# LPC176x5x register map
File version: 0.2
CPU: CM3 r0p0, little endian, no MPU, no FPU, 0x5 interrupt priority bits, 0x0 interrupts
Registers are 32-bit, read-write, no defined reset value unless marked. A register's access mark holds for its fields unless they carry their own. Offsets are from the block's base; [hi:lo] are bit positions; {n}, {i} and the like mark numbered series; 'fields as' and 'values as' point back to an identical list.

## CAN1 — CAN1 controller
Base 0x40044000
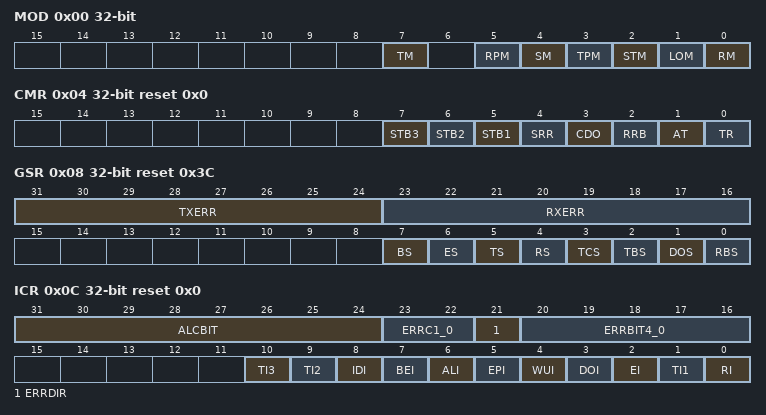
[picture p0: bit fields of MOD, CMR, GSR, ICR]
0x00 MOD — Controls the operating mode of the CAN Controller.
  [7] TM — Test Mode.
    0=DISABLED_NORMAL_OPE (Disabled. Normal operation.); 1=ENABLED_THE_TD_PIN_ (Enabled. The TD pin will reflect the bit, detected on RD pin, with the next positive edge of the system clock.)
  [5] RPM — Receive Polarity Mode.
    0=LOW_ACTIVE_RD_INPUT (Low active. RD input is active Low (dominant bit = 0).); 1=HIGH_ACTIVE_RD_INPU (High active. RD input is active High (dominant bit = 1) -- reverse polarity.)
  [4] SM — Sleep Mode.
    0=WAKE_UP_NORMAL_OPER (Wake-up. Normal operation.); 1=SLEEP_THE_CAN_CONTR (Sleep. The CAN controller enters Sleep Mode if no CAN interrupt is pending and there is no bus activity. See the Sleep Mode description Section 21.8.2 on page 565.)
  [3] TPM — Transmit Priority Mode.
    0=CAN_ID_THE_TRANSMIT (CAN ID. The transmit priority for 3 Transmit Buffers depends on the CAN Identifier.); 1=LOCAL_PRIORITY_THE_ (Local priority. The transmit priority for 3 Transmit Buffers depends on the contents of the Tx Priority register within the Transmit Buffer.)
  [2] STM — Self Test Mode.
    0=NORMAL_A_TRANSMITTE (Normal. A transmitted message must be acknowledged to be considered successful.); 1=SELF_TEST_THE_CONTR (Self test. The controller will consider a Tx message successful even if there is no acknowledgment received. In this mode a full node test is possible without any other active node on the bus using the SRR bit in CANxCMR.)
  [1] LOM — Listen Only Mode.
    0=NORMAL_THE_CAN_CONT (Normal. The CAN controller acknowledges a successfully received message on the CAN bus. The error counters are stopped at the current value.); 1=LISTEN_ONLY_THE_CON (Listen only. The controller gives no acknowledgment, even if a message is successfully received. Messages cannot be sent, and the controller operates in error passive mode. This mode is intended for software bit rate detection and hot plugging.)
  [0] RM — Reset Mode.
    0=NORMAL_THE_CAN_CONTR (Normal.The CAN Controller is in the Operating Mode, and certain registers can not be written.); 1=RESET_CAN_OPERATION (Reset. CAN operation is disabled, writable registers can be written and the current transmission/reception of a message is aborted.)
0x04 CMR wo reset 0x0 — Command bits that affect the state of the CAN Controller
  [7] STB3 — Select Tx Buffer 3.
    0=NOT_SELECTED_TX_BUF (Not selected. Tx Buffer 3 is not selected for transmission.); 1=SELECTED_TX_BUFFER_ (Selected. Tx Buffer 3 is selected for transmission.)
  [6] STB2 — Select Tx Buffer 2.
    0=NOT_SELECTED_TX_BUF (Not selected. Tx Buffer 2 is not selected for transmission.); 1=SELECTED_TX_BUFFER_ (Selected. Tx Buffer 2 is selected for transmission.)
  [5] STB1 — Select Tx Buffer 1.
    0=NOT_SELECTED_TX_BUF (Not selected. Tx Buffer 1 is not selected for transmission.); 1=SELECTED_TX_BUFFER_ (Selected. Tx Buffer 1 is selected for transmission.)
  [4] SRR — Self Reception Request.
    0=ABSENT_NO_SELF_RECE (Absent. No self reception request.); 1=PRESENT_THE_MESSAGE (Present. The message, previously written to the CANxTFS, CANxTID, and optionally the CANxTDA and CANxTDB registers, is queued for transmission from the selected Transmit Buffer and received simultaneously. This differs from the TR bit above in that the receiver is not disabled during the transmission, so that it receives the message if its Identifier is recognized by the Acceptance Filter.)
  [3] CDO — Clear Data Overrun.
    0=NO_ACTION_DO_NOT_CL (No action. Do not clear the data overrun bit.); 1=CLEAR_THE_DATA_OVER (Clear. The Data Overrun bit in Status Register(s) is cleared.)
  [2] RRB — Release Receive Buffer.
    0=NO_ACTION_DO_NOT_RE (No action. Do not release the receive buffer.); 1=RELEASED_THE_INFORM (Released. The information in the Receive Buffer (consisting of CANxRFS, CANxRID, and if applicable the CANxRDA and CANxRDB registers) is released, and becomes eligible for replacement by the next received frame. If the next received frame is not available, writing this command clears the RBS bit in the Status Register(s).)
  [1] AT — Abort Transmission.
    0=NO_ACTION_DO_NOT_AB (No action. Do not abort the transmission.); 1=PRESENT_IF_NOT_ALRE (Present. if not already in progress, a pending Transmission Request for the selected Transmit Buffer is cancelled.)
  [0] TR — Transmission Request.
    0=ABSENT_NO_TRANSMISSI (Absent.No transmission request.); 1=PRESENT_THE_MESSAGE (Present. The message, previously written to the CANxTFI, CANxTID, and optionally the CANxTDA and CANxTDB registers, is queued for transmission from the selected Transmit Buffer. If at two or all three of STB1, STB2 and STB3 bits are selected when TR=1 is written, Transmit Buffer will be selected based on the chosen priority scheme (for details see Section 21.5.3 Transmit Buffers (TXB)))
0x08 GSR ro reset 0x3C — Global Controller Status and Error Counters. The error counters can only be written when RM in CANMOD is 1.
  [31:24] TXERR — The current value of the Tx Error Counter (an 8-bit value).
  [23:16] RXERR — The current value of the Rx Error Counter (an 8-bit value).
  [7] BS — Bus Status. Mode bit '1' (present) and an Error Warning Interrupt is generated, if enabled. Afterwards the Transmit Error Counter is set to '127', and the Receive Error Counter is cleared. It will stay in this mode until the CPU clears the Reset Mode bit. Once this is completed the CAN Controller will wait the minimum protocol-defined time (128 occurrences of the Bus-Free signal) counting down the Transmit Error Counter. After that, the Bus Status bit is cleared (Bus-On), the Error Status bit is set '0' (ok), the Error Counters are reset, and an Error Warning Interrupt is generated, if enabled. Reading the TX Error Counter during this time gives information about the status of the Bus-Off recovery.
    0=BUS_ON_THE_CAN_CONT (Bus-on. The CAN Controller is involved in bus activities); 1=BUS_OFF_THE_CAN_CON (Bus-off. The CAN controller is currently not involved/prohibited from bus activity because the Transmit Error Counter reached its limiting value of 255.)
  [6] ES — Error Status. Errors detected during reception or transmission will effect the error counters according to the CAN specification. The Error Status bit is set when at least one of the error counters has reached or exceeded the Error Warning Limit. An Error Warning Interrupt is generated, if enabled. The default value of the Error Warning Limit after hardware reset is 96 decimal, see also Section 21.7.7 CAN Error Warning Limit register (CAN1EWL - 0x4004 4018, CAN2EWL - 0x4004 8018).
    0=OK_BOTH_ERROR_COUNT (OK. Both error counters are below the Error Warning Limit.); 1=ERROR_ONE_OR_BOTH_O (Error. One or both of the Transmit and Receive Error Counters has reached the limit set in the Error Warning Limit register.)
  [5] TS — Transmit Status. If both the Receive Status and the Transmit Status bits are '0' (idle), the CAN-Bus is idle. If both bits are set, the controller is waiting to become idle again. After hardware reset 11 consecutive recessive bits have to be detected until idle status is reached. After Bus-off this will take 128 times of 11 consecutive recessive bits.
    0=IDLE_THE_CAN_CONTRO (Idle. The CAN controller is idle.); 1=TRANSMIT_THE_CAN_CO (Transmit. The CAN controller is sending a message.)
  [4] RS — Receive Status. If both the Receive Status and the Transmit Status bits are '0' (idle), the CAN-Bus is idle. If both bits are set, the controller is waiting to become idle again. After hardware reset 11 consecutive recessive bits have to be detected until idle status is reached. After Bus-off this will take 128 times of 11 consecutive recessive bits.
    0=IDLE_THE_CAN_CONTRO (Idle. The CAN controller is idle.); 1=RECEIVE_THE_CAN_CON (Receive. The CAN controller is receiving a message.)
  [3] TCS — Transmit Complete Status. The Transmission Complete Status bit is set '0' (incomplete) whenever the Transmission Request bit or the Self Reception Request bit is set '1' at least for one of the three Transmit Buffers. The Transmission Complete Status bit will remain '0' until all messages are transmitted successfully.
    0=INCOMPLETE_AT_LEAST (Incomplete. At least one requested transmission has not been successfully completed yet.); 1=COMPLETE_ALL_REQUES (Complete. All requested transmission(s) has (have) been successfully completed.)
  [2] TBS — Transmit Buffer Status.
    0=LOCKED_AT_LEAST_ONE (Locked. At least one of the Transmit Buffers is not available for the CPU, i.e. at least one previously queued message for this CAN controller has not yet been sent, and therefore software should not write to the CANxTFI, CANxTID, CANxTDA, nor CANxTDB registers of that (those) Tx buffer(s).); 1=RELEASED_ALL_THREE_ (Released. All three Transmit Buffers are available for the CPU. No transmit message is pending for this CAN controller (in any of the 3 Tx buffers), and software may write to any of the CANxTFI, CANxTID, CANxTDA, and CANxTDB registers.)
  [1] DOS — Data Overrun Status. If there is not enough space to store the message within the Receive Buffer, that message is dropped and the Data Overrun condition is signalled to the CPU in the moment this message becomes valid. If this message is not completed successfully (e.g. because of an error), no overrun condition is signalled.
    0=ABSENT_NO_DATA_OVER (Absent. No data overrun has occurred since the last Clear Data Overrun command was given/written to CANxCMR (or since Reset).); 1=OVERRUN_A_MESSAGE_W (Overrun. A message was lost because the preceding message to this CAN controller was not read and released quickly enough (there was not enough space for a new message in the Double Receive Buffer).)
  [0] RBS — Receive Buffer Status. After reading all messages and releasing their memory space with the command 'Release Receive Buffer,' this bit is cleared.
    0=EMPTY_NO_MESSAGE_IS (Empty. No message is available.); 1=FULL_AT_LEAST_ONE_C (Full. At least one complete message is received by the Double Receive Buffer and available in the CANxRFS, CANxRID, and if applicable the CANxRDA and CANxRDB registers. This bit is cleared by the Release Receive Buffer command in CANxCMR, if no subsequent received message is available.)
0x0C ICR ro reset 0x0 — Interrupt status, Arbitration Lost Capture, Error Code Capture
  [31:24] ALCBIT — Each time arbitration is lost while trying to send on the CAN, the bit number within the frame is captured into this field. After the content of ALCBIT is read, the ALI bit is cleared and a new Arbitration Lost interrupt can occur. 00 = arbitration lost in the first bit (MS) of identifier ... 11 = arbitration lost in SRTS bit (RTR bit for standard frame messages) 12 = arbitration lost in IDE bit 13 = arbitration lost in 12th bit of identifier (extended frame only) ... 30 = arbitration lost in last bit of identifier (extended frame only) 31 = arbitration lost in RTR bit (extended frame only) On arbitration lost, the corresponding arbitration lost interrupt is forced, if enabled. At that time, the current bit position of the Bit Stream Processor is captured into the Arbitration Lost Capture Register. The content within this register is fixed until the user application has read out its contents once. From now on, the capture mechanism is activated again.
  [23:22] ERRC1_0 — When the CAN controller detects a bus error, the type of error is captured in this field:
    0=BIT_ERROR; 1=FORM_ERROR; 2=STUFF_ERROR; 3=OTHER_ERROR
  [21] ERRDIR — When the CAN controller detects a bus error, the direction of the current bit is captured in this bit.
    0=ERROR_OCCURRED_DURIN (Error occurred during transmitting.); 1=ERROR_OCCURRED_DURIN (Error occurred during receiving.)
  [20:16] ERRBIT4_0 — Error Code Capture: when the CAN controller detects a bus error, the location of the error within the frame is captured in this field. The value reflects an internal state variable, and as a result is not very linear: 00011 = Start of Frame 00010 = ID28 ... ID21 00110 = ID20 ... ID18 00100 = SRTR Bit 00101 = IDE bit 00111 = ID17 ... 13 01111 = ID12 ... ID5 01110 = ID4 ... ID0 01100 = RTR Bit 01101 = Reserved Bit 1 01001 = Reserved Bit 0 01011 = Data Length Code 01010 = Data Field 01000 = CRC Sequence 11000 = CRC Delimiter 11001 = Acknowledge Slot 11011 = Acknowledge Delimiter 11010 = End of Frame 10010 = Intermission Whenever a bus error occurs, the corresponding bus error interrupt is forced, if enabled. At the same time, the current position of the Bit Stream Processor is captured into the Error Code Capture Register. The content within this register is fixed until the user software has read out its content once. From now on, the capture mechanism is activated again, i.e. reading the CANxICR enables another Bus Error Interrupt.
  [10] TI3 — Transmit Interrupt 3. This bit is set when the TBS3 bit in CANxSR goes from 0 to 1 (whenever a message out of TXB3 was successfully transmitted or aborted), indicating that Transmit buffer 3 is available, and the TIE3 bit in CANxIER is 1.
    0=RESET; 1=SET
  [9] TI2 — Transmit Interrupt 2. This bit is set when the TBS2 bit in CANxSR goes from 0 to 1 (whenever a message out of TXB2 was successfully transmitted or aborted), indicating that Transmit buffer 2 is available, and the TIE2 bit in CANxIER is 1.
    0=RESET; 1=SET
  [8] IDI — ID Ready Interrupt -- this bit is set if the IDIE bit in CANxIER is 1, and a CAN Identifier has been received (a message was successfully transmitted or aborted). This bit is set whenever a message was successfully transmitted or aborted and the IDIE bit is set in the IER register.
    0=RESET; 1=SET
  [7] BEI — Bus Error Interrupt -- this bit is set if the BEIE bit in CANxIER is 1, and the CAN controller detects an error on the bus.
    0=RESET; 1=SET
  [6] ALI — Arbitration Lost Interrupt. This bit is set if the ALIE bit in CANxIER is 1, and the CAN controller loses arbitration while attempting to transmit. In this case the CAN node becomes a receiver.
    0=RESET; 1=SET
  [5] EPI — Error Passive Interrupt. This bit is set if the EPIE bit in CANxIER is 1, and the CAN controller switches between Error Passive and Error Active mode in either direction. This is the case when the CAN Controller has reached the Error Passive Status (at least one error counter exceeds the CAN protocol defined level of 127) or if the CAN Controller is in Error Passive Status and enters the Error Active Status again.
    0=RESET; 1=SET
  [4] WUI — Wake-Up Interrupt. This bit is set if the CAN controller is sleeping and bus activity is detected and the WUIE bit in CANxIER is 1. A Wake-Up Interrupt is also generated if the CPU tries to set the Sleep bit while the CAN controller is involved in bus activities or a CAN Interrupt is pending. The WUI flag can also get asserted when the according enable bit WUIE is not set. In this case a Wake-Up Interrupt does not get asserted.
    0=RESET; 1=SET
  [3] DOI — Data Overrun Interrupt. This bit is set when the DOS bit in CANxSR goes from 0 to 1 and the DOIE bit in CANxIER is 1.
    0=RESET; 1=SET
  [2] EI — Error Warning Interrupt. This bit is set on every change (set or clear) of either the Error Status or Bus Status bit in CANxSR and the EIE bit bit is set within the Interrupt Enable Register at the time of the change.
    0=RESET; 1=SET
  [1] TI1 — Transmit Interrupt 1. This bit is set when the TBS1 bit in CANxSR goes from 0 to 1 (whenever a message out of TXB1 was successfully transmitted or aborted), indicating that Transmit buffer 1 is available, and the TIE1 bit in CANxIER is 1.
    0=RESET; 1=SET
  [0] RI — Receive Interrupt. This bit is set whenever the RBS bit in CANxSR and the RIE bit in CANxIER are both 1, indicating that a new message was received and stored in the Receive Buffer. The Receive Interrupt Bit is not cleared upon a read access to the Interrupt Register. Giving the Command Release Receive Buffer will clear RI temporarily. If there is another message available within the Receive Buffer after the release command, RI is set again. Otherwise RI remains cleared.
    0=RESET; 1=SET
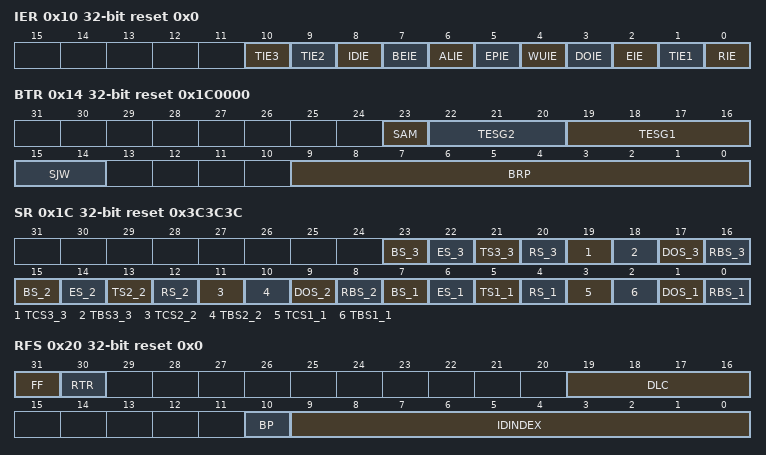
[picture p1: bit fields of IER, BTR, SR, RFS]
0x10 IER reset 0x0 — Interrupt Enable
  [10] TIE3 — Transmit Interrupt Enable for Buffer3. When a message has been successfully transmitted out of TXB3 or Transmit Buffer 3 is accessible again (e.g. after an Abort Transmission command), the CAN Controller requests the respective interrupt.
  [9] TIE2 — Transmit Interrupt Enable for Buffer2. When a message has been successfully transmitted out of TXB2 or Transmit Buffer 2 is accessible again (e.g. after an Abort Transmission command), the CAN Controller requests the respective interrupt.
  [8] IDIE — ID Ready Interrupt Enable. When a CAN identifier has been received, the CAN Controller requests the respective interrupt.
  [7] BEIE — Bus Error Interrupt Enable. If a bus error has been detected, the CAN Controller requests the respective interrupt.
  [6] ALIE — Arbitration Lost Interrupt Enable. If the CAN Controller has lost arbitration, the respective interrupt is requested.
  [5] EPIE — Error Passive Interrupt Enable. If the error status of the CAN Controller changes from error active to error passive or vice versa, the respective interrupt is requested.
  [4] WUIE — Wake-Up Interrupt Enable. If the sleeping CAN controller wakes up, the respective interrupt is requested.
  [3] DOIE — Data Overrun Interrupt Enable. If the Data Overrun Status bit is set (see Status Register), the CAN Controller requests the respective interrupt.
  [2] EIE — Error Warning Interrupt Enable. If the Error or Bus Status change (see Status Register), the CAN Controller requests the respective interrupt.
  [1] TIE1 — Transmit Interrupt Enable for Buffer1. When a message has been successfully transmitted out of TXB1 or Transmit Buffer 1 is accessible again (e.g. after an Abort Transmission command), the CAN Controller requests the respective interrupt.
  [0] RIE — Receiver Interrupt Enable. When the Receive Buffer Status is 'full', the CAN Controller requests the respective interrupt.
0x14 BTR reset 0x1C0000 — Bus Timing. Can only be written when RM in CANMOD is 1.
  [23] SAM — Sampling
    0=THE_BUS_IS_SAMPLED_O (The bus is sampled once (recommended for high speed buses)); 1=THE_BUS_IS_SAMPLED_3 (The bus is sampled 3 times (recommended for low to medium speed buses to filter spikes on the bus-line))
  [22:20] TESG2 — The delay from the sample point to the next nominal sync point is (this value plus one) CAN clocks. The nominal CAN bit time is (this value plus the value in TSEG1 plus 3) CAN clocks.
  [19:16] TESG1 — The delay from the nominal Sync point to the sample point is (this value plus one) CAN clocks.
  [15:14] SJW — The Synchronization Jump Width is (this value plus one) CAN clocks.
  [9:0] BRP — Baud Rate Prescaler. The APB clock is divided by (this value plus one) to produce the CAN clock.
0x18 EWL reset 0x60 — Error Warning Limit. Can only be written when RM in CANMOD is 1.
  [7:0] EWL — During CAN operation, this value is compared to both the Tx and Rx Error Counters. If either of these counter matches this value, the Error Status (ES) bit in CANSR is set.
0x1C SR ro reset 0x3C3C3C — Status Register
  [23] BS_3 — Bus Status. This bit is identical to the BS bit in the CANxGSR.
  [22] ES_3 — Error Status. This bit is identical to the ES bit in the CANxGSR.
  [21] TS3_3 — Transmit Status 3.
    0=IDLE_THERE_IS_NO_TR (Idle. There is no transmission from Tx Buffer 3.); 1=TRANSMIT_THE_CAN_CO (Transmit. The CAN Controller is transmitting a message from Tx Buffer 3.)
  [20] RS_3 — Receive Status. This bit is identical to the RS bit in the GSR.
  [19] TCS3_3 — Transmission Complete Status.
    0=INCOMPLETE_THE_PREV (Incomplete. The previously requested transmission for Tx Buffer 3 is not complete.); 1=COMPLETE_THE_PREVIO (Complete. The previously requested transmission for Tx Buffer 3 has been successfully completed.)
  [18] TBS3_3 — Transmit Buffer Status 3.
    0=LOCKED_SOFTWARE_CAN (Locked. Software cannot access the Tx Buffer 3 nor write to the corresponding CANxTFI, CANxTID, CANxTDA, and CANxTDB registers because a message is either waiting for transmission or is in transmitting process.); 1=RELEASED_SOFTWARE_M (Released. Software may write a message into the Transmit Buffer 3 and its CANxTFI, CANxTID, CANxTDA, and CANxTDB registers.)
  [17] DOS_3 — Data Overrun Status. This bit is identical to the DOS bit in the CANxGSR.
  [16] RBS_3 — Receive Buffer Status. This bit is identical to the RBS bit in the CANxGSR.
  [15] BS_2 — Bus Status. This bit is identical to the BS bit in the CANxGSR.
  [14] ES_2 — Error Status. This bit is identical to the ES bit in the CANxGSR.
  [13] TS2_2 — Transmit Status 2.
    0=IDLE_THERE_IS_NO_TR (Idle. There is no transmission from Tx Buffer 2.); 1=TRANSMIT_THE_CAN_CO (Transmit. The CAN Controller is transmitting a message from Tx Buffer 2.)
  [12] RS_2 — Receive Status. This bit is identical to the RS bit in the GSR.
  [11] TCS2_2 — Transmission Complete Status.
    0=INCOMPLETE_THE_PREV (Incomplete. The previously requested transmission for Tx Buffer 2 is not complete.); 1=COMPLETE_THE_PREVIO (Complete. The previously requested transmission for Tx Buffer 2 has been successfully completed.)
  [10] TBS2_2 — Transmit Buffer Status 2.
    0=LOCKED_SOFTWARE_CAN (Locked. Software cannot access the Tx Buffer 2 nor write to the corresponding CANxTFI, CANxTID, CANxTDA, and CANxTDB registers because a message is either waiting for transmission or is in transmitting process.); 1=RELEASED_SOFTWARE_M (Released. Software may write a message into the Transmit Buffer 2 and its CANxTFI, CANxTID, CANxTDA, and CANxTDB registers.)
  [9] DOS_2 — Data Overrun Status. This bit is identical to the DOS bit in the CANxGSR.
  [8] RBS_2 — Receive Buffer Status. This bit is identical to the RBS bit in the CANxGSR.
  [7] BS_1 — Bus Status. This bit is identical to the BS bit in the CANxGSR.
  [6] ES_1 — Error Status. This bit is identical to the ES bit in the CANxGSR.
  [5] TS1_1 — Transmit Status 1.
    0=IDLE_THERE_IS_NO_TR (Idle. There is no transmission from Tx Buffer 1.); 1=TRANSMIT_THE_CAN_CO (Transmit. The CAN Controller is transmitting a message from Tx Buffer 1.)
  [4] RS_1 — Receive Status. This bit is identical to the RS bit in the GSR.
  [3] TCS1_1 — Transmission Complete Status.
    0=INCOMPLETE_THE_PREV (Incomplete. The previously requested transmission for Tx Buffer 1 is not complete.); 1=COMPLETE_THE_PREVIO (Complete. The previously requested transmission for Tx Buffer 1 has been successfully completed.)
  [2] TBS1_1 — Transmit Buffer Status 1.
    0=LOCKED_SOFTWARE_CAN (Locked. Software cannot access the Tx Buffer 1 nor write to the corresponding CANxTFI, CANxTID, CANxTDA, and CANxTDB registers because a message is either waiting for transmission or is in transmitting process.); 1=RELEASED_SOFTWARE_M (Released. Software may write a message into the Transmit Buffer 1 and its CANxTFI, CANxTID, CANxTDA, and CANxTDB registers.)
  [1] DOS_1 — Data Overrun Status. This bit is identical to the DOS bit in the CANxGSR.
  [0] RBS_1 — Receive Buffer Status. This bit is identical to the RBS bit in the CANxGSR.
0x20 RFS reset 0x0 — Receive frame status. Can only be written when RM in CANMOD is 1.
  [31] FF — A 0 in this bit indicates that the current received message included an 11-bit Identifier, while a 1 indicates a 29-bit Identifier. This affects the contents of the CANid register described below.
  [30] RTR — This bit contains the Remote Transmission Request bit of the current received message. 0 indicates a Data Frame, in which (if DLC is non-zero) data can be read from the CANRDA and possibly the CANRDB registers. 1 indicates a Remote frame, in which case the DLC value identifies the number of data bytes requested to be sent using the same Identifier.
  [19:16] DLC — The field contains the Data Length Code (DLC) field of the current received message. When RTR = 0, this is related to the number of data bytes available in the CANRDA and CANRDB registers as follows: 0000-0111 = 0 to 7 bytes1000-1111 = 8 bytes With RTR = 1, this value indicates the number of data bytes requested to be sent back, with the same encoding.
  [10] BP — If this bit is 1, the current message was received in AF Bypass mode, and the ID Index field (above) is meaningless.
  [9:0] IDINDEX — ID Index. If the BP bit (below) is 0, this value is the zero-based number of the Lookup Table RAM entry at which the Acceptance Filter matched the received Identifier. Disabled entries in the Standard tables are included in this numbering, but will not be matched. See Section 21.17 Examples of acceptance filter tables and ID index values on page 587 for examples of ID Index values.
0x24 RID reset 0x0 — Received Identifier. Can only be written when RM in CANMOD is 1.
  [10:0] ID — The 11-bit Identifier field of the current received message. In CAN 2.0A, these bits are called ID10-0, while in CAN 2.0B they're called ID29-18.
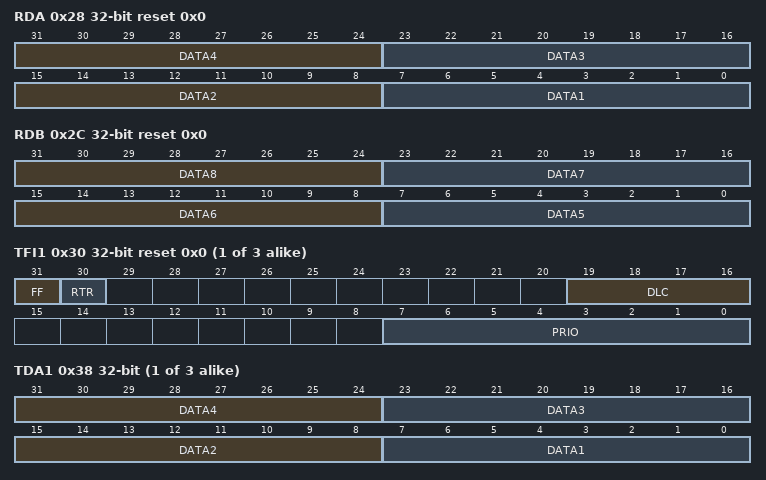
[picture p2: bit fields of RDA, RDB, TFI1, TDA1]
0x28 RDA reset 0x0 — Received data bytes 1-4. Can only be written when RM in CANMOD is 1.
  [31:24] DATA4 — Data 4. If the DLC field in CANRFS >= 0100, this contains the first Data byte of the current received message.
  [23:16] DATA3 — Data 3. If the DLC field in CANRFS >= 0011, this contains the first Data byte of the current received message.
  [15:8] DATA2 — Data 2. If the DLC field in CANRFS >= 0010, this contains the first Data byte of the current received message.
  [7:0] DATA1 — Data 1. If the DLC field in CANRFS >= 0001, this contains the first Data byte of the current received message.
0x2C RDB reset 0x0 — Received data bytes 5-8. Can only be written when RM in CANMOD is 1.
  [31:24] DATA8 — Data 8. If the DLC field in CANRFS >= 1000, this contains the first Data byte of the current received message.
  [23:16] DATA7 — Data 7. If the DLC field in CANRFS >= 0111, this contains the first Data byte of the current received message.
  [15:8] DATA6 — Data 6. If the DLC field in CANRFS >= 0110, this contains the first Data byte of the current received message.
  [7:0] DATA5 — Data 5. If the DLC field in CANRFS >= 0101, this contains the first Data byte of the current received message.
{0x20+0x10*i} TFI{i} reset 0x0 (i=1..3) — Transmit frame info (Tx Buffer )
  [31] FF — If this bit is 0, the next transmit message will be sent with an 11-bit Identifier (standard frame format), while if it's 1, the message will be sent with a 29-bit Identifier (extended frame format).
  [30] RTR — This value is sent in the RTR bit of the next transmit message. If this bit is 0, the number of data bytes called out by the DLC field are sent from the CANxTDA and CANxTDB registers. If this bit is 1, a Remote Frame is sent, containing a request for that number of bytes.
  [19:16] DLC — Data Length Code. This value is sent in the DLC field of the next transmit message. In addition, if RTR = 0, this value controls the number of Data bytes sent in the next transmit message, from the CANxTDA and CANxTDB registers: 0000-0111 = 0-7 bytes 1xxx = 8 bytes
  [7:0] PRIO — If the TPM (Transmit Priority Mode) bit in the CANxMOD register is set to 1, enabled Tx Buffers contend for the right to send their messages based on this field. The buffer with the lowest TX Priority value wins the prioritization and is sent first.
{0x24+0x10*i} TID{i} reset 0x0 (i=1..3) — Transmit Identifier (Tx Buffer)
  [10:0] ID — The 11-bit Identifier to be sent in the next transmit message.
{0x28+0x10*i} TDA{i} (i=1..3) — Transmit data bytes 1-4 (Tx Buffer)
  [31:24] DATA4 — Data 4. If RTR = 0 and DLC >= 0100 in the corresponding CANxTFI, this byte is sent as the 4th Data byte of the next transmit message.
  [23:16] DATA3 — Data 3. If RTR = 0 and DLC >= 0011 in the corresponding CANxTFI, this byte is sent as the 3rd Data byte of the next transmit message.
  [15:8] DATA2 — Data 2. If RTR = 0 and DLC >= 0010 in the corresponding CANxTFI, this byte is sent as the 2nd Data byte of the next transmit message.
  [7:0] DATA1 — Data 1. If RTR = 0 and DLC >= 0001 in the corresponding CANxTFI, this byte is sent as the first Data byte of the next transmit message.
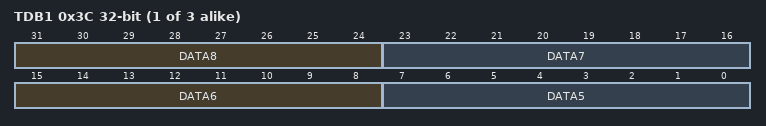
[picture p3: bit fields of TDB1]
{0x2C+0x10*i} TDB{i} (i=1..3) — Transmit data bytes 5-8 (Tx Buffer )
  [31:24] DATA8 — Data 8. If RTR = 0 and DLC >= 1000 in the corresponding CANTFI, this byte is sent as the 8th Data byte of the next transmit message.
  [23:16] DATA7 — Data 7. If RTR = 0 and DLC >= 0111 in the corresponding CANTFI, this byte is sent as the 7th Data byte of the next transmit message.
  [15:8] DATA6 — Data 6. If RTR = 0 and DLC >= 0110 in the corresponding CANTFI, this byte is sent as the 6th Data byte of the next transmit message.
  [7:0] DATA5 — Data 5. If RTR = 0 and DLC >= 0101 in the corresponding CANTFI, this byte is sent as the 5th Data byte of the next transmit message.

## CAN2 — CAN1 controller
Base 0x40048000
Registers as CAN1; these are added or differ:
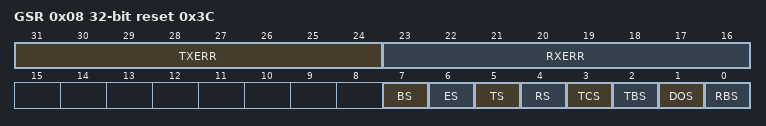
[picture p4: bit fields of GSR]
0x08 GSR ro reset 0x3C — Global Controller Status and Error Counters. The error counters can only be written when RM in CANMOD is 1.
  fields as CAN1.GSR
